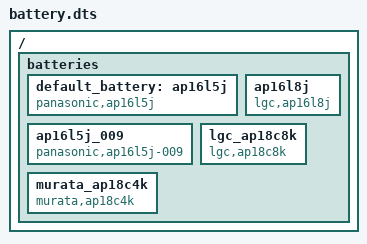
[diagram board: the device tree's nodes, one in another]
/* Copyright 2021 The Chromium OS Authors. All rights reserved.
 * Use of this source code is governed by a BSD-style license that can be
 * found in the LICENSE file.
 */

/ {
	batteries {
		default_battery: ap16l5j {
			compatible = "panasonic,ap16l5j";
		};
		ap16l5j_009 {
			compatible = "panasonic,ap16l5j-009";
		};
		ap16l8j {
			compatible = "lgc,ap16l8j";
		};
		lgc_ap18c8k {
			compatible = "lgc,ap18c8k";
		};
		murata_ap18c4k {
			compatible = "murata,ap18c4k";
		};
	};
};
